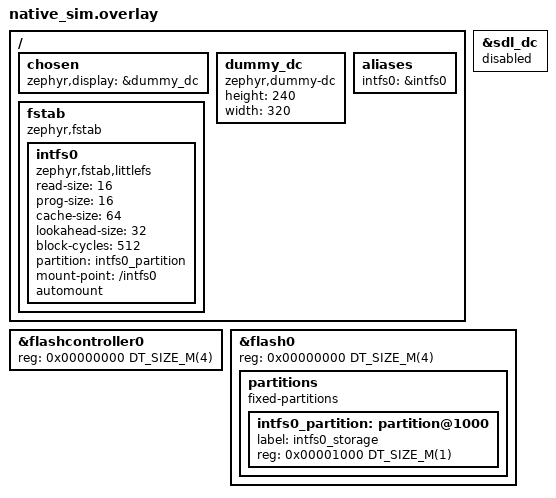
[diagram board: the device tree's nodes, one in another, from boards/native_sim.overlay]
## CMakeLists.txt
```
cmake_minimum_required(VERSION 3.20.0)

set(RT_GAUGE_TEST_SIM_FLASH ON)
include(${CMAKE_CURRENT_SOURCE_DIR}/../../../rt_gauge_test.cmake)

# Use Zephyr's build system
find_package(Zephyr REQUIRED HINTS $ENV{ZEPHYR_BASE})
project(functional_display_domain)

include_directories(${APP_SRC_DIR})

set(APP_SRC_CONFIGURATION_DIR ${APP_SRC_DIR}/configuration)
file(GLOB_RECURSE APP_SRC_CONFIGURATION
  ${APP_SRC_CONFIGURATION_DIR}/*.c
  ${APP_SRC_CONFIGURATION_DIR}/*.cpp
)

# The configuration half of the domain builds everywhere.
set(APP_SRC_DISPLAY_DOMAIN_DIR ${APP_SRC_DIR}/domain/display_domain)
file(GLOB_RECURSE APP_SRC_DISPLAY_DOMAIN
  ${APP_SRC_DISPLAY_DOMAIN_DIR}/configuration/*.c
  ${APP_SRC_DISPLAY_DOMAIN_DIR}/configuration/*.cpp
)

file(GLOB_RECURSE TEST_SOURCES src/*.c src/*.cpp)

# DisplayService talks to the display driver, which only native_sim binds here (the dummy display of
# boards/native_sim.overlay): the service and its tests are built where the display driver is on.
if(CONFIG_DISPLAY)
  list(APPEND APP_SRC_DISPLAY_DOMAIN
    ${APP_SRC_DISPLAY_DOMAIN_DIR}/services/display_service.cpp
    ${APP_SRC_DIR}/domain/ui_domain/lvgl_lock.cpp
  )
else()
  list(REMOVE_ITEM TEST_SOURCES ${CMAKE_CURRENT_SOURCE_DIR}/src/display_service_brightness.cpp)
endif()

# Add all source files to the app target
target_sources(app PRIVATE
  ${APP_SRC_CONFIGURATION}
  ${APP_SRC_DISPLAY_DOMAIN}
  ${TEST_SOURCES}
)
```

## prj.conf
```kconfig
CONFIG_ZTEST=y

#HW Version
CONFIG_EERIE_LEAP_HW_VERSION_MAJOR=2
CONFIG_EERIE_LEAP_HW_VERSION_MINOR=9
CONFIG_EERIE_LEAP_HW_VERSION_PATCH=6

#SW Version
CONFIG_EERIE_LEAP_SW_VERSION_MAJOR=7
CONFIG_EERIE_LEAP_SW_VERSION_MINOR=8
CONFIG_EERIE_LEAP_SW_VERSION_PATCH=4

# Language and Compiler
CONFIG_CPP=y
CONFIG_PICOLIBC=y
CONFIG_STD_CPP23=y
CONFIG_REQUIRES_FULL_LIBCPP=y
CONFIG_CPP_EXCEPTIONS=y
CONFIG_CPP_RTTI=y

# Memory
# The sensor events channel alone queues 128 events. Stay below 256 KB: a larger pool needs
# CONFIG_SYS_HEAP_AUTO or fails to init at boot.
CONFIG_HEAP_MEM_POOL_SIZE=196608

# C++ exception unwinding needs considerably more stack than the ztest defaults.
CONFIG_MAIN_STACK_SIZE=8192
CONFIG_ZTEST_STACK_SIZE=8192

# Logging And Debugging
CONFIG_LOG=y
CONFIG_TEST_RANDOM_GENERATOR=y
CONFIG_THREAD_ANALYZER=y
CONFIG_THREAD_ANALYZER_USE_LOG=y
CONFIG_THREAD_RUNTIME_STATS=y
CONFIG_THREAD_NAME=y
CONFIG_SYS_HEAP_RUNTIME_STATS=y
CONFIG_THREAD_ANALYZER_ISR_STACK_USAGE=n

# FS Config
CONFIG_FLASH=y
CONFIG_FLASH_MAP=y
CONFIG_FILE_SYSTEM=y
CONFIG_FILE_SYSTEM_LITTLEFS=y
CONFIG_FILE_SYSTEM_MKFS=y

# CBOR
CONFIG_ZCBOR=y

CONFIG_CRC=y
CONFIG_TIMING_FUNCTIONS=y

CONFIG_EERIE_LEAP_RT_CORE=y
CONFIG_EERIE_LEAP_CONFIGURATION=y
CONFIG_EERIE_LEAP_DEVICE_TREE=y
CONFIG_EERIE_LEAP_EVENT_BUS=y
CONFIG_EERIE_LEAP_FS=y
CONFIG_EERIE_LEAP_RANDOM=y
CONFIG_EERIE_LEAP_TIME=y
CONFIG_EERIE_LEAP_LUA_SCRIPT=y
CONFIG_EERIE_LEAP_EXPRESSION_ENGINE=y
```

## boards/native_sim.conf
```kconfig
CONFIG_FLASH_SIMULATOR=y

# DisplayService drives the dummy display of native_sim.overlay; no other board here has a display.
CONFIG_DISPLAY=y
```

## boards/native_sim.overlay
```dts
/ {
	/*
	 * DisplayService drives the panel through the display API; the dummy display accepts every call,
	 * and sdl_dc stays off so the suite needs no SDL.
	 */
	chosen {
		zephyr,display = &dummy_dc;
	};

	dummy_dc: dummy_dc {
		compatible = "zephyr,dummy-dc";
		height = <240>;
		width = <320>;
	};

	aliases {
		intfs0 = &intfs0;
	};

	fstab {
		compatible = "zephyr,fstab";
		intfs0: intfs0 {
			compatible = "zephyr,fstab,littlefs";
			read-size = <16>;
			prog-size = <16>;
			cache-size = <64>;
			lookahead-size = <32>;
			block-cycles = <512>;
			partition = <&intfs0_partition>;
			mount-point = "/intfs0";
			automount;
		};
	};
};

&sdl_dc {
	status = "disabled";
};

&flashcontroller0 {
	reg = <0x00000000 DT_SIZE_M(4)>;  // 4MB flash controller
};

// HEX Flash dump can be found in the duild/flash.bin file
&flash0 {
	reg = <0x00000000 DT_SIZE_M(4)>;  // 4MB total flash

	partitions {
		compatible = "fixed-partitions";
		#address-cells = <1>;
		#size-cells = <1>;

		intfs0_partition: partition@1000 {
			label = "intfs0_storage";
			reg = <0x00001000 DT_SIZE_M(1)>;  // 0x00001000 offset, 1MB size
		};
	};
};
```

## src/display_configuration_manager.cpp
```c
#include <array>
#include <memory>
#include <span>
#include <string>
#include <string_view>
#include <utility>
#include <variant>
#include <vector>

#include <zephyr/kernel.h>
#include <zephyr/ztest.h>

#include "configuration/cbor/cbor_display_config/cbor_display_config.h"
#include "configuration/services/cbor_configuration_service.h"
#include "utilities/cbor/cbor_helpers.hpp"

#include "domain/configuration_domain/services/configuration_service.h"
#include "domain/display_domain/configuration/display_configuration_manager.h"
#include "domain/display_domain/models/display_configuration.h"
#include "domain/sensor_domain/event_bus/sensor_event_type.h"
#include "domain/sensor_domain/event_bus/sensor_payload_type.h"

#include "subsys/device_tree/dt_fs.h"
#include "subsys/event_bus/event_binding.h"
#include "subsys/fs/services/fs_service.h"

using eerie_leap::configuration::cbor::CborSerializer;
using eerie_leap::configuration::services::CborConfigurationService;
using eerie_leap::domain::configuration_domain::services::ConfigurationService;
using eerie_leap::domain::display_domain::configuration::DisplayConfigurationManager;
using eerie_leap::domain::display_domain::models::DisplayConfiguration;
using eerie_leap::domain::sensor_domain::event_bus::SensorEventType;
using eerie_leap::domain::sensor_domain::event_bus::SensorPayloadType;
using eerie_leap::subsys::device_tree::DtFs;
using eerie_leap::subsys::event_bus::EventBinding;
using eerie_leap::subsys::event_bus::EventChannelId;
using eerie_leap::subsys::fs::services::FsService;
using eerie_leap::utilities::cbor::CborHelpers;

namespace {

std::shared_ptr<DisplayConfigurationManager> MakeManager() {
    DtFs::InitInternalFs();
    auto fs_service = std::make_shared<FsService>(DtFs::GetInternalFsMp());

    fs_service->Format();

    auto cbor_display_configuration_service = std::make_unique<CborConfigurationService<CborDisplayConfig>>(
        "display_config", fs_service
    );

    return std::make_shared<DisplayConfigurationManager>(std::move(cbor_display_configuration_service));
}

DisplayConfiguration MakeConfiguration() {
    DisplayConfiguration configuration;
    configuration.brightness = 42;
    configuration.blanking_enabled = true;
    configuration.screen_timeout_s = 90;
    configuration.theme_id = 4;
    configuration.brightness_sensor_id = "ambient_light";

    return configuration;
}

} // namespace

ZTEST_SUITE(display_configuration_manager, NULL, NULL, NULL, NULL, NULL);

ZTEST(display_configuration_manager, test_an_empty_filesystem_yields_the_default_configuration) {
    auto manager = MakeManager();

    auto configuration = manager->Get();

    zassert_not_null(configuration.get());
    zassert_equal(configuration->brightness, 160);
    zassert_false(configuration->blanking_enabled);
    zassert_true(configuration->brightness_sensor_id.empty(), "No sensor drives the brightness.");
}

ZTEST(display_configuration_manager, test_update_round_trips_through_flash) {
    auto manager = MakeManager();

    zassert_true(manager->Update(MakeConfiguration()));

    auto stored = manager->Get(true);

    zassert_equal(stored->brightness, 42);
    zassert_true(stored->blanking_enabled);
    zassert_equal(stored->screen_timeout_s, 90);
    zassert_equal(stored->theme_id, 4);
    zassert_str_equal(stored->brightness_sensor_id.c_str(), "ambient_light");
}

ZTEST(display_configuration_manager, test_cbor_configuration_round_trips) {
    auto manager = MakeManager();

    zassert_true(manager->Update(MakeConfiguration()));

    auto cbor = manager->GetCborConfiguration();
    zassert_true(!cbor.empty());

    DisplayConfiguration replacement;
    replacement.brightness = 7;
    zassert_true(manager->Update(replacement));
    zassert_equal(manager->Get(true)->brightness, 7);

    zassert_true(manager->ApplyCborConfiguration(std::span<const uint8_t>(cbor.data(), cbor.size())));

    auto restored = manager->Get(true);
    zassert_equal(restored->brightness, 42);
    zassert_true(restored->blanking_enabled);
    zassert_equal(restored->screen_timeout_s, 90);
    zassert_str_equal(restored->brightness_sensor_id.c_str(), "ambient_light");
}

// A configuration pushed from outside has to reach the driver without a reboot.
ZTEST(display_configuration_manager, test_apply_cbor_configuration_notifies_the_handler) {
    auto manager = MakeManager();

    zassert_true(manager->Update(MakeConfiguration()));
    auto cbor = manager->GetCborConfiguration();

    int notifications = 0;
    manager->RegisterConfigurationUpdatedHandler([&notifications] {
        notifications++;
    });

    // A local update is the service telling the manager what it already applied.
    zassert_true(manager->Update(MakeConfiguration()));
    zassert_equal(notifications, 0);

    zassert_true(manager->ApplyCborConfiguration(std::span<const uint8_t>(cbor.data(), cbor.size())));
    zassert_equal(notifications, 1);
}

ZTEST(display_configuration_manager, test_a_throwing_handler_does_not_fail_the_apply) {
    auto manager = MakeManager();

    zassert_true(manager->Update(MakeConfiguration()));
    auto cbor = manager->GetCborConfiguration();

    manager->RegisterConfigurationUpdatedHandler([] {
        throw std::runtime_error("boom");
    });

    zassert_true(manager->ApplyCborConfiguration(std::span<const uint8_t>(cbor.data(), cbor.size())));
}

ZTEST(display_configuration_manager, test_garbage_cbor_is_rejected) {
    auto manager = MakeManager();

    zassert_true(manager->Update(MakeConfiguration()));

    std::vector<uint8_t> garbage = { 0xFF, 0xFF, 0xFF, 0xFF };

    std::array<char, 96> reason{};
    zassert_false(manager->ApplyCborConfiguration(std::span<const uint8_t>(garbage.data(), garbage.size()), reason));
    zassert_str_equal(reason.data(), "Malformed CBOR");
    zassert_equal(manager->Get(true)->brightness, 42);
}

ZTEST(display_configuration_manager, test_a_rejected_configuration_reports_why) {
    auto manager = MakeManager();
    zassert_true(manager->Update(MakeConfiguration()));

    CborSerializer<CborDisplayConfig> serializer;
    const auto exported = manager->GetCborConfiguration();
    auto cbor_config = serializer.Deserialize(exported);
    zassert_not_null(cbor_config.get());
    cbor_config->brightness = 300;

    int notifications = 0;
    manager->RegisterConfigurationUpdatedHandler([&notifications] {
        notifications++;
    });

    ConfigurationService configuration_service;
    configuration_service.RegisterCborConfigurationManager(ConfigurationService::Type::Display, manager);

    std::array<char, 96> reason{};
    zassert_false(configuration_service.ApplyCborConfiguration(
        ConfigurationService::Type::Display, serializer.Serialize(*cbor_config), reason
    ));
    zassert_str_equal(
        reason.data(), "Invalid Display configuration. Brightness must be between 0 and 255. Value: 300."
    );
    zassert_equal(notifications, 0);
    zassert_equal(manager->Get(true)->brightness, 42);
}

// The sensor a client names has to be a sensor ID, whatever else the unit checks about it.
ZTEST(display_configuration_manager, test_a_brightness_sensor_id_that_is_not_a_sensor_id_is_rejected) {
    auto manager = MakeManager();
    zassert_true(manager->Update(MakeConfiguration()));

    CborSerializer<CborDisplayConfig> serializer;
    const auto exported = manager->GetCborConfiguration();
    auto cbor_config = serializer.Deserialize(exported);
    zassert_not_null(cbor_config.get());

    const std::string sensor_id = "1st_sensor";
    cbor_config->brightness_sensor_id = CborHelpers::ToZcborString(sensor_id);

    ConfigurationService configuration_service;
    configuration_service.RegisterCborConfigurationManager(ConfigurationService::Type::Display, manager);

    std::array<char, 160> reason{};
    zassert_false(configuration_service.ApplyCborConfiguration(
        ConfigurationService::Type::Display, serializer.Serialize(*cbor_config), reason
    ));
    zassert_str_equal(
        reason.data(),
        "Invalid Display configuration. Brightness sensor ID must start with a letter or an underscore. Value: "
        "1st_sensor."
    );
    zassert_str_equal(manager->Get(true)->brightness_sensor_id.c_str(), "ambient_light");
}

ZTEST(display_configuration_manager, test_update_refuses_a_brightness_sensor_id_that_is_not_a_sensor_id) {
    auto manager = MakeManager();
    zassert_true(manager->Update(MakeConfiguration()));

    auto configuration = MakeConfiguration();
    configuration.brightness_sensor_id = "ambient-light";

    zassert_false(manager->Update(configuration));
    zassert_str_equal(manager->Get(true)->brightness_sensor_id.c_str(), "ambient_light");
}

ZTEST(display_configuration_manager, test_the_configuration_service_routes_the_display_type) {
    auto manager = MakeManager();
    zassert_true(manager->Update(MakeConfiguration()));

    ConfigurationService configuration_service;
    configuration_service.RegisterCborConfigurationManager(ConfigurationService::Type::Display, manager);

    auto cbor = configuration_service.GetCborConfiguration(ConfigurationService::Type::Display);
    zassert_true(!cbor.empty());

    DisplayConfiguration replacement;
    replacement.brightness = 9;
    zassert_true(manager->Update(replacement));

    zassert_true(configuration_service.ApplyCborConfiguration(
        ConfigurationService::Type::Display, std::span<const uint8_t>(cbor.data(), cbor.size())
    ));

    zassert_equal(manager->Get(true)->brightness, 42);
}

// Logging learns of a configuration update from the service (ConfigurationUpdateLoggingStop): a write
// from outside and a local Update() are reported, the unit's own setting is not.
ZTEST(display_configuration_manager, test_update_and_apply_are_reported_to_the_configuration_service) {
    auto manager = MakeManager();
    ConfigurationService configuration_service;
    configuration_service.RegisterCborConfigurationManager(ConfigurationService::Type::Display, manager);

    std::vector<ConfigurationService::Type> reports;
    configuration_service.RegisterConfigurationStoredHandler([&reports](ConfigurationService::Type type) {
        reports.push_back(type);
    });

    zassert_true(manager->Update(MakeConfiguration()));
    zassert_equal(reports.size(), 1U);
    zassert_equal(reports[0], ConfigurationService::Type::Display);

    const auto cbor = configuration_service.GetCborConfiguration(ConfigurationService::Type::Display);
    zassert_true(configuration_service.ApplyCborConfiguration(
        ConfigurationService::Type::Display, std::span<const uint8_t>(cbor.data(), cbor.size())
    ));
    zassert_equal(reports.size(), 2U, "and so is an apply, which also tells the driver's handler");

    std::vector<uint8_t> garbage = { 0xFF, 0xFF, 0xFF, 0xFF };
    zassert_false(configuration_service.ApplyCborConfiguration(ConfigurationService::Type::Display, garbage));
    zassert_equal(reports.size(), 2U, "A rejected write is not");

    configuration_service.RegisterConfigurationStoredHandler(nullptr);
}

// The brightness the gauge's own slider sets is stored like any configuration, as the display
// configuration, but it is the unit's own setting: it stops no logging.
ZTEST(display_configuration_manager, test_update_own_setting_is_not_reported) {
    auto manager = MakeManager();
    ConfigurationService configuration_service;
    configuration_service.RegisterCborConfigurationManager(ConfigurationService::Type::Display, manager);

    int reports = 0;
    configuration_service.RegisterConfigurationStoredHandler([&reports](ConfigurationService::Type) {
        reports++;
    });

    int notifications = 0;
    manager->RegisterConfigurationUpdatedHandler([&notifications] {
        notifications++;
    });

    zassert_true(manager->UpdateOwnSetting(MakeConfiguration()));

    zassert_equal(manager->Get(true)->brightness, 42, "The setting is stored");
    zassert_equal(reports, 0, "and no update is reported");
    zassert_equal(notifications, 0);

    configuration_service.RegisterConfigurationStoredHandler(nullptr);
}

// A client's apply asks about the sensor the brightness follows, as the binding DisplayService subscribes with.
ZTEST(display_configuration_manager, test_an_apply_asks_the_checker_about_the_brightness_sensor) {
    auto manager = MakeManager();

    std::vector<EventBinding> asked;
    manager->SetBrightnessSensorChecker([&asked](const EventBinding& binding) {
        asked.push_back(binding);

        return std::string_view();
    });

    zassert_true(manager->Update(MakeConfiguration()), "A save is not checked");
    zassert_true(asked.empty());
    const auto cbor = manager->GetCborConfiguration();

    zassert_true(manager->ApplyCborConfiguration(std::span<const uint8_t>(cbor.data(), cbor.size())));

    zassert_equal(asked.size(), 1U);
    zassert_equal(asked[0].channel, EventChannelId::Sensors);
    zassert_equal(asked[0].event_type, std::to_underlying(SensorEventType::DataUpdated));
    zassert_equal(asked[0].payload_key, std::to_underlying(SensorPayloadType::Value));
    zassert_equal(asked[0].selector_key, std::to_underlying(SensorPayloadType::SensorId));
    zassert_true(std::get<std::pmr::string>(asked[0].selector_value) == "ambient_light");
    zassert_equal(manager->Get(true)->brightness, 42);
}

ZTEST(display_configuration_manager, test_an_apply_is_refused_when_the_checker_refuses_the_brightness_sensor) {
    auto manager = MakeManager();
    manager->SetBrightnessSensorChecker([](const EventBinding&) {
        return std::string_view("names a sensor that is not analog.");
    });

    zassert_true(manager->Update(MakeConfiguration()), "A save is not checked");
    const auto cbor = manager->GetCborConfiguration();

    DisplayConfiguration replacement;
    replacement.brightness = 7;
    zassert_true(manager->Update(replacement));

    int notifications = 0;
    manager->RegisterConfigurationUpdatedHandler([&notifications] {
        notifications++;
    });

    std::array<char, 160> reason{};
    zassert_false(manager->ApplyCborConfiguration(std::span<const uint8_t>(cbor.data(), cbor.size()), reason));
    zassert_str_equal(
        reason.data(), "Invalid Display configuration. Brightness sensor ID names a sensor that is not analog."
    );
    zassert_equal(manager->Get(true)->brightness, 7, "A refused apply stores nothing");
    zassert_equal(notifications, 0);
}

// No sensor to follow is nothing to check.
ZTEST(display_configuration_manager, test_an_apply_without_a_brightness_sensor_does_not_ask_the_checker) {
    auto manager = MakeManager();

    int asked = 0;
    manager->SetBrightnessSensorChecker([&asked](const EventBinding&) {
        asked++;

        return std::string_view("names a sensor this unit does not have.");
    });

    auto configuration = MakeConfiguration();
    configuration.brightness_sensor_id.clear();
    zassert_true(manager->Update(configuration));
    const auto cbor = manager->GetCborConfiguration();

    zassert_true(manager->ApplyCborConfiguration(std::span<const uint8_t>(cbor.data(), cbor.size())));

    zassert_equal(asked, 0);
    zassert_true(manager->Get(true)->brightness_sensor_id.empty());
}

ZTEST(display_configuration_manager, test_an_apply_without_a_brightness_sensor_checker_is_not_checked) {
    auto manager = MakeManager();

    zassert_true(manager->Update(MakeConfiguration()));
    const auto cbor = manager->GetCborConfiguration();

    zassert_true(manager->ApplyCborConfiguration(std::span<const uint8_t>(cbor.data(), cbor.size())));
    zassert_str_equal(manager->Get(true)->brightness_sensor_id.c_str(), "ambient_light");
}
```

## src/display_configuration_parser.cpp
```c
#include <cstdint>
#include <stdexcept>
#include <string>
#include <string_view>
#include <utility>

#include <zephyr/ztest.h>

#include "configuration/cbor/cbor_display_config/cbor_display_config.h"
#include "configuration/cbor/cbor_serializer.h"
#include "utilities/cbor/cbor_helpers.hpp"
#include "utilities/memory/memory_resource_manager.h"

#include "domain/display_domain/configuration/parsers/display_configuration_cbor_parser.h"
#include "domain/display_domain/models/display_configuration.h"

using eerie_leap::configuration::cbor::CborSerializer;
using eerie_leap::domain::display_domain::configuration::parsers::DisplayConfigurationCborParser;
using eerie_leap::domain::display_domain::models::DisplayConfiguration;
using eerie_leap::utilities::cbor::CborHelpers;
using eerie_leap::utilities::memory::Mrm;

namespace {

template<typename Fn>
std::string ThrownMessage(Fn&& fn) {
    try {
        std::forward<Fn>(fn)();
    } catch(const std::exception& e) {
        return e.what();
    } catch(...) {
        return "unexpected exception";
    }

    return "no exception";
}

// The text of @p sensor_id is not copied: it has to outlive the result.
CborDisplayConfig MakeCborConfig(std::string_view sensor_id) {
    CborDisplayConfig config{};
    config.version = DisplayConfigurationCborParser::CONFIGURATION_VERSION;
    config.brightness = 200;
    config.blanking_enabled = true;
    config.screen_timeout_s = 45;
    config.theme_id = 3;
    config.brightness_sensor_id = CborHelpers::ToZcborString(sensor_id);

    return config;
}

DisplayConfiguration MakeConfiguration(std::string_view sensor_id) {
    DisplayConfiguration configuration;
    configuration.brightness_sensor_id = sensor_id;

    return configuration;
}

std::string_view View(const DisplayConfiguration& configuration) {
    return configuration.brightness_sensor_id;
}

} // namespace

ZTEST_SUITE(display_configuration_parser, NULL, NULL, NULL, NULL, NULL);

ZTEST(display_configuration_parser, test_the_brightness_sensor_id_round_trips) {
    const auto configuration = MakeConfiguration("ambient_light");

    auto config = DisplayConfigurationCborParser::Serialize(configuration);
    zassert_equal(config->version, DisplayConfigurationCborParser::CONFIGURATION_VERSION);
    zassert_equal(CborHelpers::ToStringView(config->brightness_sensor_id), "ambient_light");

    auto restored = DisplayConfigurationCborParser::Deserialize(Mrm::GetDefaultPmr(), *config);

    zassert_equal(View(*restored), "ambient_light");
}

// None is the default, and what a configuration without the field decodes to.
ZTEST(display_configuration_parser, test_no_brightness_sensor_is_accepted) {
    const DisplayConfiguration configuration{};
    zassert_true(configuration.brightness_sensor_id.empty());

    auto config = DisplayConfigurationCborParser::Serialize(configuration);
    zassert_equal(config->brightness_sensor_id.len, 0U);
    zassert_true(
        DisplayConfigurationCborParser::Deserialize(Mrm::GetDefaultPmr(), *config)->brightness_sensor_id.empty()
    );

    auto unset = MakeCborConfig("");
    unset.brightness_sensor_id = {};
    zassert_true(
        DisplayConfigurationCborParser::Deserialize(Mrm::GetDefaultPmr(), unset)->brightness_sensor_id.empty()
    );
}

ZTEST(display_configuration_parser, test_the_text_the_codec_carries_is_the_text_that_was_stored) {
    // Longer than 23 bytes, so its length takes a byte of its own.
    const auto configuration = MakeConfiguration("a_sensor_with_a_rather_long_identifier_2");

    CborSerializer<CborDisplayConfig> serializer;
    const auto bytes = serializer.Serialize(*DisplayConfigurationCborParser::Serialize(configuration));
    zassert_false(bytes.empty(), "Expected the configuration to encode.");

    const auto decoded = serializer.Deserialize(bytes);
    zassert_not_null(decoded.get());

    auto restored = DisplayConfigurationCborParser::Deserialize(Mrm::GetDefaultPmr(), *decoded);

    zassert_equal(View(*restored), "a_sensor_with_a_rather_long_identifier_2");
    zassert_equal(restored->brightness, configuration.brightness);
}

ZTEST(display_configuration_parser, test_an_id_that_is_a_sensor_id_is_accepted) {
    for(const std::string_view sensor_id : { "a", "A", "_", "ambient_light", "_ambient", "sensor_1", "S1_x_9" }) {
        const auto config = MakeCborConfig(sensor_id);
        auto restored = DisplayConfigurationCborParser::Deserialize(Mrm::GetDefaultPmr(), config);

        zassert_equal(View(*restored), sensor_id);
    }
}

ZTEST(display_configuration_parser, test_an_id_that_does_not_start_like_a_sensor_id_is_refused) {
    for(const std::string_view sensor_id : { "1abc", "9", "-a", " a", ".a" }) {
        const auto config = MakeCborConfig(sensor_id);
        const auto message = ThrownMessage([&] {
            DisplayConfigurationCborParser::Deserialize(Mrm::GetDefaultPmr(), config);
        });

        zassert_equal(
            message,
            "Invalid Display configuration. Brightness sensor ID must start with a letter or an underscore. Value: "
                + std::string(sensor_id) + ".",
            "%s", message.c_str()
        );
    }
}

ZTEST(display_configuration_parser, test_an_id_with_a_character_a_sensor_id_cannot_have_is_refused) {
    for(const std::string_view sensor_id : { "a-b", "a b", "a.b", "a/b", "ab " }) {
        const auto config = MakeCborConfig(sensor_id);
        const auto message = ThrownMessage([&] {
            DisplayConfigurationCborParser::Deserialize(Mrm::GetDefaultPmr(), config);
        });

        zassert_equal(
            message,
            "Invalid Display configuration. Brightness sensor ID must contain only letters, digits, and underscores. "
            "Value: "
                + std::string(sensor_id) + ".",
            "%s", message.c_str()
        );
    }
}

// Deserialize has to accept what Serialize produces, so Serialize refuses what Deserialize would.
ZTEST(display_configuration_parser, test_serialize_refuses_an_id_that_is_not_a_sensor_id) {
    for(const std::string_view sensor_id : { "1abc", "a-b" }) {
        const auto configuration = MakeConfiguration(sensor_id);
        const auto message = ThrownMessage([&] {
            DisplayConfigurationCborParser::Serialize(configuration);
        });

        zassert_true(
            message.starts_with("Invalid Display configuration. Brightness sensor ID must "), "%s", message.c_str()
        );
    }
}
```

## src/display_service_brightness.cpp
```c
#include <array>
#include <cstdint>
#include <limits>
#include <memory>
#include <optional>
#include <string>
#include <string_view>

#include <zephyr/kernel.h>
#include <zephyr/ztest.h>

#include "configuration/cbor/cbor_display_config/cbor_display_config.h"
#include "configuration/services/cbor_configuration_service.h"
#include "subsys/device_tree/dt_display.h"
#include "subsys/device_tree/dt_fs.h"
#include "subsys/event_bus/event.h"
#include "subsys/event_bus/event_bus.h"
#include "subsys/event_bus/event_channel.h"
#include "subsys/event_bus/event_channel_id.h"
#include "subsys/event_bus/event_channel_registry.h"
#include "subsys/fs/services/fs_service.h"
#include "subsys/threading/work_queue_thread.h"
#include "utilities/memory/memory_resource_manager.h"
#include "utilities/string/string_helpers.h"

#include "domain/display_domain/configuration/display_configuration_manager.h"
#include "domain/display_domain/models/display_configuration.h"
#include "domain/display_domain/services/display_service.h"
#include "domain/sensor_domain/event_bus/sensor_events_channel.h"
#include "domain/settings_domain/event_bus/settings_events_channel.h"
#include "domain/settings_domain/models/setting_id.h"

using eerie_leap::configuration::services::CborConfigurationService;
using eerie_leap::domain::display_domain::configuration::DisplayConfigurationManager;
using eerie_leap::domain::display_domain::models::DisplayConfiguration;
using eerie_leap::domain::display_domain::services::DisplayService;
using eerie_leap::domain::sensor_domain::event_bus::SensorEventsChannel;
using eerie_leap::domain::sensor_domain::event_bus::SensorEventType;
using eerie_leap::domain::sensor_domain::event_bus::SensorPayloadType;
using eerie_leap::domain::settings_domain::event_bus::SettingsEventsChannel;
using eerie_leap::domain::settings_domain::event_bus::SettingsEventType;
using eerie_leap::domain::settings_domain::event_bus::SettingsPayloadType;
using eerie_leap::domain::settings_domain::models::SettingId;
using eerie_leap::subsys::device_tree::DtDisplay;
using eerie_leap::subsys::device_tree::DtFs;
using eerie_leap::subsys::event_bus::AnySubscription;
using eerie_leap::subsys::event_bus::CreateScopedSubscription;
using eerie_leap::subsys::event_bus::EventBus;
using eerie_leap::subsys::event_bus::EventChannelId;
using eerie_leap::subsys::event_bus::EventChannelRegistry;
using eerie_leap::subsys::event_bus::EventData;
using eerie_leap::subsys::fs::services::FsService;
using eerie_leap::subsys::threading::WorkQueueThread;
using eerie_leap::utilities::memory::Mrm;
using eerie_leap::utilities::string::StringHelpers;

namespace {

constexpr std::string_view SENSOR_ID = "ambient_light";
constexpr std::string_view OTHER_SENSOR_ID = "screen_dimmer";
constexpr uint32_t SOURCE_ID = 0x7E57;
constexpr int DISPATCH_TIMEOUT_MS = 1000;
constexpr int NO_DISPATCH_TIMEOUT_MS = 200;
constexpr int BUS_STACK_SIZE = 4096;
constexpr int WORK_QUEUE_STACK_SIZE = 8192;
constexpr int WORK_QUEUE_PRIORITY = 10;

// The channels are inert until a bus drains them, so the suite owns one for the two the service uses.
class TestEventBus : public EventBus {
public:
    TestEventBus() :
        EventBus("display_service_test_bus", BUS_STACK_SIZE) {
        RegisterChannel(SensorEventsChannel::GetInstance());
        RegisterChannel(SettingsEventsChannel::GetInstance());
    }
};

// The configuration work queue the service persists on, and the configuration files are saved on. One
// thread for the whole suite, its stack from the external PMR as EventBus takes its own.
std::shared_ptr<WorkQueueThread> SharedWorkQueue() {
    static std::shared_ptr<WorkQueueThread> queue = [] {
        auto created = std::make_shared<WorkQueueThread>(
            "display_service_test_wq", WORK_QUEUE_STACK_SIZE, WORK_QUEUE_PRIORITY, false, Mrm::GetExtPmr()
        );

        created->Initialize();

        return created;
    }();

    return queue;
}

// Returns once everything queued before the call has run.
bool FlushQueue(WorkQueueThread& queue) {
    auto done = std::make_shared<k_sem>();
    k_sem_init(done.get(), 0, 1);

    queue.Run([done] {
        k_sem_give(done.get());
    });

    return k_sem_take(done.get(), K_SECONDS(5)) == 0;
}

uint32_t BrightnessId() {
    return StringHelpers::GetHash(SettingId::DISPLAY_BRIGHTNESS);
}

// What a widget bound to the brightness setting sees: the values of its Changed events, in order.
class ChangedProbe {
public:
    ChangedProbe() :
        state_(std::make_shared<State>()) {
        k_msgq_init(&state_->queue, state_->storage.data(), sizeof(int), CAPACITY);

        subscription_ = CreateScopedSubscription(
            SettingsEventsChannel::GetInstance(), SettingsEventType::Changed,
            [state = state_](const SettingsEventsChannel::EventMessage& event) {
                const auto* const id = event.payload.find(SettingsPayloadType::SettingId);
                const auto* const value = event.payload.find(SettingsPayloadType::Value);
                if(id == event.payload.end() || value == event.payload.end())
                    return;

                const auto* setting_id = std::get_if<uint32_t>(&id->second);
                const auto* brightness = std::get_if<int>(&value->second);
                if(setting_id == nullptr || *setting_id != BrightnessId() || brightness == nullptr)
                    return;

                const int delivered = *brightness;
                k_msgq_put(&state->queue, &delivered, K_NO_WAIT);
            }
        );
    }

    [[nodiscard]] bool IsSubscribed() const {
        return subscription_ != nullptr;
    }

    // The next value, or none when no Changed event arrives in time.
    std::optional<int> Next() {
        int value = 0;
        if(k_msgq_get(&state_->queue, &value, K_MSEC(DISPATCH_TIMEOUT_MS)) != 0)
            return std::nullopt;

        return value;
    }

    // Whether the service published nothing while a Changed event had every chance to arrive.
    bool WaitForNoEvent() {
        int value = 0;

        return k_msgq_get(&state_->queue, &value, K_MSEC(NO_DISPATCH_TIMEOUT_MS)) != 0;
    }

private:
    static constexpr uint32_t CAPACITY = 16;

    struct State {
        k_msgq queue{};
        alignas(int) std::array<char, CAPACITY * sizeof(int)> storage{};
    };

    std::shared_ptr<State> state_;
    AnySubscription subscription_;
};

DisplayConfiguration MakeConfiguration(uint8_t brightness, std::string_view sensor_id = {}) {
    DisplayConfiguration configuration;
    configuration.brightness = brightness;
    configuration.brightness_sensor_id = sensor_id;

    return configuration;
}

// A display service over a freshly formatted file system, started on the configuration it is given as
// the stored one. The probe sees what the service tells the UI, the initial value included, which is
// taken here.
class Harness {
public:
    std::shared_ptr<DisplayConfigurationManager> manager;
    ChangedProbe changed;
    std::unique_ptr<DisplayService> service;

    explicit Harness(const DisplayConfiguration& stored) {
        DtDisplay::Initialize();
        DtFs::InitInternalFs();

        auto fs_service = std::make_shared<FsService>(DtFs::GetInternalFsMp());
        fs_service->Format();

        manager = std::make_shared<DisplayConfigurationManager>(
            std::make_unique<CborConfigurationService<CborDisplayConfig>>(
                "display_config", fs_service, SharedWorkQueue()
            )
        );
        zassert_true(manager->Update(stored), "Expected the configuration to be stored.");

        zassert_true(changed.IsSubscribed());

        service = std::make_unique<DisplayService>(manager, SharedWorkQueue());
        zassert_equal(service->Initialize(), 0, "Expected the display service to initialize.");

        const auto initial = changed.Next();
        zassert_true(initial.has_value(), "The service publishes the brightness it starts with.");
        zassert_equal(*initial, static_cast<int>(stored.brightness));
    }

    // The configuration as it is on flash.
    [[nodiscard]] uint8_t StoredBrightness() const {
        return manager->Get(true)->brightness;
    }

    // A sensor's committed value, as the sensor events publisher publishes it. Published in place, so the
    // service has handled it when this returns.
    static void PublishSensorValue(std::string_view sensor_id, const EventData& value) {
        SensorEventsChannel::GetInstance().Publish(
            { .source_id = SOURCE_ID,
                .type = SensorEventType::DataUpdated,
                .payload = { { SensorPayloadType::SensorId, StringHelpers::GetHash(sensor_id) },
                    { SensorPayloadType::Value, value } } }
        );
    }

    // What a widget bound to the setting sends when the person moves it.
    static void RequestBrightness(int brightness) {
        SettingsEventsChannel::GetInstance().Publish(
            { .source_id = SOURCE_ID,
                .type = SettingsEventType::ChangeRequested,
                .payload = {
                    { SettingsPayloadType::SettingId, BrightnessId() }, { SettingsPayloadType::Value, brightness } } }
        );
    }

    // What SettingsPersistenceService requests once a second has passed without a change, and the write
    // the service makes of it, finished.
    static void RequestPersist() {
        SettingsEventsChannel::GetInstance().Publish(
            { .source_id = SOURCE_ID,
                .type = SettingsEventType::PersistRequested,
                .payload = { { SettingsPayloadType::SettingId, BrightnessId() } } }
        );

        zassert_true(FlushQueue(*SharedWorkQueue()), "Expected the persist request to have run.");
    }
};

void* StartEventBus() {
    static TestEventBus bus;

    // What an event binding resolves the sensors channel through.
    EventChannelRegistry::GetInstance().Register(EventChannelId::Sensors, SensorEventsChannel::GetInstance());

    return nullptr;
}

// Lets what the last test published drain before the next one subscribes.
void SettleEventBus(void*) {
    k_msleep(NO_DISPATCH_TIMEOUT_MS);
}

} // namespace

ZTEST_SUITE(display_service_brightness, NULL, StartEventBus, NULL, SettleEventBus, NULL);

ZTEST(display_service_brightness, test_the_panel_starts_at_the_stored_brightness) {
    Harness harness(MakeConfiguration(42, SENSOR_ID));

    zassert_equal(harness.service->GetBrightness(), 42);
}

ZTEST(display_service_brightness, test_a_named_sensors_value_sets_the_brightness_and_is_published) {
    Harness harness(MakeConfiguration(42, SENSOR_ID));

    Harness::PublishSensorValue(SENSOR_ID, 100.0F);

    zassert_equal(harness.service->GetBrightness(), 100);
    zassert_equal(harness.changed.Next(), std::optional<int>(100), "Expected the value as it settled.");

    // An int is a number too.
    Harness::PublishSensorValue(SENSOR_ID, 77);

    zassert_equal(harness.service->GetBrightness(), 77);
    zassert_equal(harness.changed.Next(), std::optional<int>(77));
}

ZTEST(display_service_brightness, test_a_followed_value_is_clamped_like_a_request) {
    Harness harness(MakeConfiguration(42, SENSOR_ID));

    Harness::PublishSensorValue(SENSOR_ID, 3.0F);

    zassert_equal(harness.service->GetBrightness(), 10, "The floor keeps the panel findable.");
    zassert_equal(harness.changed.Next(), std::optional<int>(10));

    Harness::PublishSensorValue(SENSOR_ID, 1000.0F);

    zassert_equal(harness.service->GetBrightness(), 255);
    zassert_equal(harness.changed.Next(), std::optional<int>(255));

    // It is the clamped value that must have moved: this one settles where the panel already is.
    Harness::PublishSensorValue(SENSOR_ID, 5000.0F);

    zassert_equal(harness.service->GetBrightness(), 255);
    zassert_true(harness.changed.WaitForNoEvent(), "A value that moved nothing is no fact.");
}

ZTEST(display_service_brightness, test_another_sensors_value_is_not_followed) {
    Harness harness(MakeConfiguration(42, SENSOR_ID));

    Harness::PublishSensorValue(OTHER_SENSOR_ID, 100.0F);

    zassert_equal(harness.service->GetBrightness(), 42);
    zassert_true(harness.changed.WaitForNoEvent());
}

ZTEST(display_service_brightness, test_with_no_sensor_named_nothing_is_followed) {
    Harness harness(MakeConfiguration(42));

    Harness::PublishSensorValue(SENSOR_ID, 100.0F);
    Harness::PublishSensorValue(OTHER_SENSOR_ID, 100.0F);

    zassert_equal(harness.service->GetBrightness(), 42);
    zassert_true(harness.changed.WaitForNoEvent());
}

ZTEST(display_service_brightness, test_a_value_that_is_not_a_number_is_ignored) {
    Harness harness(MakeConfiguration(42, SENSOR_ID));

    Harness::PublishSensorValue(SENSOR_ID, std::numeric_limits<float>::quiet_NaN());
    Harness::PublishSensorValue(SENSOR_ID, std::string("bright"));

    zassert_equal(harness.service->GetBrightness(), 42);
    zassert_true(harness.changed.WaitForNoEvent());
}

ZTEST(display_service_brightness, test_a_value_published_on_the_bus_is_followed) {
    Harness harness(MakeConfiguration(42, SENSOR_ID));

    // As the sensor events publisher publishes it: queued, and delivered on the bus worker.
    SensorEventsChannel::GetInstance().PublishAsync(
        { .source_id = SOURCE_ID,
            .type = SensorEventType::DataUpdated,
            .payload = { { SensorPayloadType::SensorId, StringHelpers::GetHash(SENSOR_ID) },
                { SensorPayloadType::Value, 120.0F } } }
    );

    zassert_equal(harness.changed.Next(), std::optional<int>(120));
    zassert_equal(harness.service->GetBrightness(), 120);
}

// The request after a quiet second finds nothing to write: the brightness on the panel is not the stored one.
ZTEST(display_service_brightness, test_a_followed_value_is_never_written) {
    Harness harness(MakeConfiguration(42, SENSOR_ID));

    // The stored configuration changes behind the service's back: whatever the service wrote would undo it.
    zassert_true(harness.manager->Update(MakeConfiguration(77, SENSOR_ID)));

    Harness::PublishSensorValue(SENSOR_ID, 100.0F);
    zassert_equal(harness.service->GetBrightness(), 100);

    Harness::RequestPersist();

    zassert_equal(harness.StoredBrightness(), 77, "Nothing was written.");
}

ZTEST(display_service_brightness, test_a_manual_change_applies_and_is_written) {
    Harness harness(MakeConfiguration(42, SENSOR_ID));

    Harness::RequestBrightness(200);

    zassert_equal(harness.service->GetBrightness(), 200);
    zassert_equal(harness.changed.Next(), std::optional<int>(200));
    zassert_equal(harness.StoredBrightness(), 42, "It is written with the persist request, not before.");

    Harness::RequestPersist();

    zassert_equal(harness.StoredBrightness(), 200);
}

ZTEST(display_service_brightness, test_the_next_sensor_value_moves_the_panel_and_not_the_stored_brightness) {
    Harness harness(MakeConfiguration(42, SENSOR_ID));

    Harness::RequestBrightness(200);
    zassert_equal(harness.changed.Next(), std::optional<int>(200));
    Harness::RequestPersist();
    zassert_equal(harness.StoredBrightness(), 200);

    Harness::PublishSensorValue(SENSOR_ID, 90.0F);

    zassert_equal(harness.service->GetBrightness(), 90, "The latest change wins.");
    zassert_equal(harness.changed.Next(), std::optional<int>(90));

    // The stored brightness is still the person's, and a persist request writes nothing over it.
    zassert_true(harness.manager->Update(MakeConfiguration(55, SENSOR_ID)));
    Harness::RequestPersist();

    zassert_equal(harness.StoredBrightness(), 55, "Nothing was written.");
}

// A request for the value a sensor put on the panel moves nothing on the panel, but it is the person's
// choice and becomes the stored brightness.
ZTEST(display_service_brightness, test_a_manual_change_to_the_value_a_sensor_set_is_stored) {
    Harness harness(MakeConfiguration(42, SENSOR_ID));

    Harness::PublishSensorValue(SENSOR_ID, 100.0F);
    zassert_equal(harness.changed.Next(), std::optional<int>(100));

    Harness::RequestBrightness(100);

    zassert_equal(harness.service->GetBrightness(), 100);
    zassert_equal(harness.changed.Next(), std::optional<int>(100), "The persist debounce is re-armed.");

    Harness::RequestPersist();

    zassert_equal(harness.StoredBrightness(), 100);
}

ZTEST(display_service_brightness, test_a_reload_with_another_sensor_follows_the_new_sensor) {
    Harness harness(MakeConfiguration(42, SENSOR_ID));

    Harness::PublishSensorValue(SENSOR_ID, 100.0F);
    zassert_equal(harness.service->GetBrightness(), 100);
    zassert_equal(harness.changed.Next(), std::optional<int>(100));

    // A client's apply stores the configuration, then has the service reload it.
    zassert_true(harness.manager->Update(MakeConfiguration(60, OTHER_SENSOR_ID)));
    zassert_equal(harness.service->Reload(), 0);

    zassert_equal(harness.service->GetBrightness(), 60, "The stored brightness is on the panel until a value comes.");
    zassert_equal(harness.changed.Next(), std::optional<int>(60));

    Harness::PublishSensorValue(SENSOR_ID, 150.0F);

    zassert_equal(harness.service->GetBrightness(), 60, "The old sensor is not followed any more.");
    zassert_true(harness.changed.WaitForNoEvent());

    Harness::PublishSensorValue(OTHER_SENSOR_ID, 180.0F);

    zassert_equal(harness.service->GetBrightness(), 180);
    zassert_equal(harness.changed.Next(), std::optional<int>(180));
}

ZTEST(display_service_brightness, test_a_reload_that_names_the_same_sensor_keeps_following_it) {
    Harness harness(MakeConfiguration(42, SENSOR_ID));

    zassert_true(harness.manager->Update(MakeConfiguration(60, SENSOR_ID)));
    zassert_equal(harness.service->Reload(), 0);
    zassert_equal(harness.changed.Next(), std::optional<int>(60));

    Harness::PublishSensorValue(SENSOR_ID, 130.0F);

    zassert_equal(harness.service->GetBrightness(), 130);
    zassert_equal(harness.changed.Next(), std::optional<int>(130));
}

ZTEST(display_service_brightness, test_a_reload_without_a_sensor_stops_following) {
    Harness harness(MakeConfiguration(42, SENSOR_ID));

    zassert_true(harness.manager->Update(MakeConfiguration(60)));
    zassert_equal(harness.service->Reload(), 0);
    zassert_equal(harness.changed.Next(), std::optional<int>(60));

    Harness::PublishSensorValue(SENSOR_ID, 150.0F);

    zassert_equal(harness.service->GetBrightness(), 60);
    zassert_true(harness.changed.WaitForNoEvent());

    // And one that names a sensor again follows it.
    zassert_true(harness.manager->Update(MakeConfiguration(60, SENSOR_ID)));
    zassert_equal(harness.service->Reload(), 0);
    zassert_equal(harness.changed.Next(), std::optional<int>(60));

    Harness::PublishSensorValue(SENSOR_ID, 150.0F);

    zassert_equal(harness.service->GetBrightness(), 150);
}

// What a client applied is on flash, and replaces a manual change that was still waiting to be written.
ZTEST(display_service_brightness, test_a_reload_takes_the_configuration_unmarked) {
    Harness harness(MakeConfiguration(42));

    Harness::RequestBrightness(200);
    zassert_equal(harness.changed.Next(), std::optional<int>(200));

    zassert_true(harness.manager->Update(MakeConfiguration(77)));
    zassert_equal(harness.service->Reload(), 0);
    zassert_equal(harness.service->GetBrightness(), 77);

    zassert_true(harness.manager->Update(MakeConfiguration(88)));
    Harness::RequestPersist();

    zassert_equal(harness.StoredBrightness(), 88, "Nothing was written.");
}
```
